# STM32MP25_CM33 register map
File version: 1.3
CPU: CM33 r0p1, little endian, MPU, FPU, vendor SysTick, 8 interrupt priority bits
Registers are 32-bit, read-write, reset 0x0 unless marked. A register's access mark holds for its fields unless they carry their own. Offsets are from the block's base; [hi:lo] are bit positions; {n}, {i} and the like mark numbered series; 'fields as' and 'values as' point back to an identical list.

## EXTI2 — EXTI2 address block description
Base 0x46230000
Same registers: EXTI2_S 0x56230000
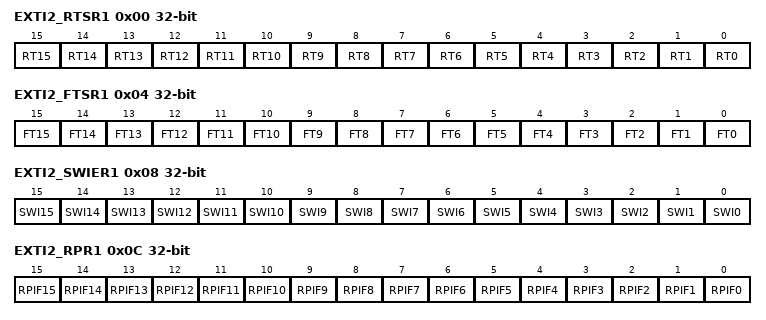
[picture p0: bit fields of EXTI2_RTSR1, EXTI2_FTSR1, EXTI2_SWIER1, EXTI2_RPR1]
0x00 EXTI2_RTSR1 — EXTI2 rising trigger selection register
  [15] RT15 — Rising trigger event configuration bit of configurable event input 15. When EXTI2_SECCFGR1.SEC15 is disabled, RT15 can be accessed with non-secure and secure access. When EXTI2_SECCFGR1.SEC15 is enabled, RT15 can only be accessed with secure access. Non-secure write to this bit x is discarded, non-secure read returns 0. When EXTI2_PRIVCFGR1.PRIV15 is disabled, RT15 can be accessed with unprivileged and privilege access. When EXTI2_PRIVCFGR1.PRIV15 is enabled, RT15 can only be accessed with privilege access. Unprivileged write to this bit x is discarded, unprivileged read returns 0. When CID filtering is disabled in EXTI2_E15CIDCFGR this RT15 can be accessed by any processor CID. When CID filtering is enabled in EXTI2_E15CIDCFGR this RT15 can only be accessed by the allowed processor CID. Illegal CID write to this RT15 is discarded and read returns 0. Note: The configurable event input is edge triggered. No glitch must be generated on this input. If a rising edge on the configurable event input occurs while writing to the register, the associated pending bit is not set. Rising and falling edge triggers can be set for the same configurable event input. In this case, both edges generate a trigger.
    0=Rising trigger disabled (for event and Interrupt) for input line; 1=Rising trigger enabled (for event and Interrupt) for input line
  [n] RT{n} (n=0..14) — Rising trigger event configuration bit of configurable event input {n}.
0x04 EXTI2_FTSR1 — EXTI2 falling trigger selection register
  [15] FT15 — Falling trigger event configuration bit of configurable event input 15. When EXTI2_SECCFGR1.SEC15 is disabled, FT15 can be accessed with non-secure and secure access. When EXTI2_SECCFGR1.SEC15 is enabled, FT15 can only be accessed with secure access. Non-secure write to this FT15 is discarded, non-secure read returns 0. When EXTI2_PRIVCFGR1.PRIV15 is disabled, FT15 can be accessed with unprivileged and privilege access. When EXTI2_PRIVCFGR1.PRIV15 is enabled, FT15 can only be accessed with privilege access. Unprivileged write to this FT15 is discarded, unprivileged read returns 0. When CID filtering is disabled in EXTI2_E15CIDCFGR this FT15 can be accessed by any processor CID. When CID filtering is enabled in EXTI2_E15CIDCFGR this FT15 can only be accessed by the allowed processor CID. Dis allowed CID write to this FT15 is discarded and read returns 0. Note: The configurable event input is edge triggered. No glitch must be generated on this input. If a falling edge on the configurable event input occurs while writing to the register, the associated pending bit is not set. Rising and falling edge triggers can be set for the same configurable event input. In this case, both edges generate a trigger.
    0=Falling trigger disabled (for event and Interrupt) for input line; 1=Falling trigger enabled (for event and Interrupt) for input line
  [n] FT{n} (n=0..14) — Falling trigger event configuration bit of configurable event input {n}.
0x08 EXTI2_SWIER1 — EXTI2 software interrupt event register
  [15] SWI15 — Software interrupt on event 15. When EXTI2_SECCFGR1.SEC15 is disabled, SWI15 can be accessed with non-secure and secure access. When EXTI2_SECCFGR1.SEC15 is enabled, SWI15 can only be accessed with secure access. Non-secure write to this SWI15 is discarded, non-secure read returns 0. When EXTI2_PRIVCFGR1.PRIV15 is disabled, SWI15 can be accessed with unprivileged and privilege access. When EXTI2_PRIVCFGR1.PRIV15 is enabled, SWI15 can only be accessed with privilege access. Unprivileged write to this SWI15 is discarded, unprivileged read returns 0. When CID filtering is disabled in EXTI2_E15CIDCFGR this SWI15 can be accessed by any processor CID. When CID filtering is enabled in EXTI2_E15CIDCFGR this SWI15 can only be accessed by the allowed processor CID. Dis allowed CID write to this SWI15 is discarded and read returns 0. A software interrupt is generated independent from the setting in EXTI2_RTSR and EXTI2_FTSR. It always returns 0 when read.
    0=Writing 0 has no effect; 1=Writing a 1 to this bit triggers a rising edge event on event 15. This bit is auto cleared by HW.
  [n] SWI{n} (n=0..14) — Software interrupt on event {n}.
0x0C EXTI2_RPR1 — EXTI2 rising edge pending register
  [15] RPIF15 — configurable event input 15 rising edge Pending bit. When EXTI2_SECCFGR1.SEC15 is disabled, RPIF15 can be accessed with non-secure and secure access. When EXTI2_SECCFGR1.SEC15 is enabled, RPIF15 can only be accessed with secure access. Non-secure write to this RPIF15 is discarded, non-secure read returns 0. When EXTI2_PRIVCFGR1.PRIV15 is disabled, RPIF15 can be accessed with unprivileged and privilege access. When EXTI2_PRIVCFGR1.PRIV15 is enabled, RPIF15 can only be accessed with privilege access. Unprivileged write to this RPIF15 is discarded, unprivileged read returns 0. When CID filtering is disabled in EXTI2_E15CIDCFGR this RPIF15 can be accessed by any processor CID. When CID filtering is enabled in EXTI2_E15CIDCFGR this RPIF15 can only be accessed by the allowed processor CID. Dis allowed CID write to this RPIF15 is discarded and read returns 0. This bit is set when the selected rising edge event or an EXTI2_SWIER Software trigger arrives on the configurable event line. This bit is cleared by writing a 1 into the bit.
    0=No rising edge trigger request occurred; 1=selected rising edge trigger request occurred
  [n] RPIF{n} (n=6..14) — configurable event input {n} rising edge Pending bit.
  [5] RPIF5 — configurable event input 5 rising edge Pending bit
  [n] RPIF{n} (n=0..4) — configurable event input {n} rising edge Pending bit.
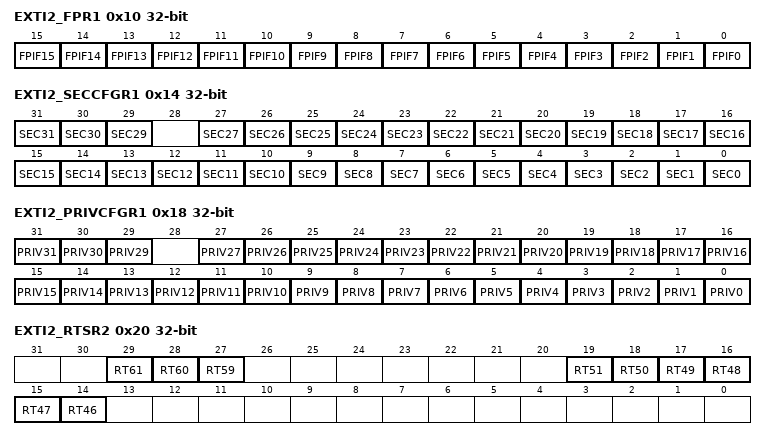
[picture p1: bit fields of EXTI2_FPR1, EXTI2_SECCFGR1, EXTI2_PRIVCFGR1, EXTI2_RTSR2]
0x10 EXTI2_FPR1 — EXTI2 falling edge pending register
  [15] FPIF15 — configurable event input 15 falling edge pending bit. When EXTI2_SECCFGR1.SEC15 is disabled, FPIF15 can be accessed with non-secure and secure access. When EXTI2_SECCFGR1.SEC15 is enabled, FPIF15 can only be accessed with secure access. Non-secure write to this FPIF15 is discarded, non-secure read returns 0. When EXTI2_PRIVCFGR1.PRIV15 is disabled, FPIF15 can be accessed with unprivileged and privilege access. When EXTI2_PRIVCFGR1.PRIV15 is enabled, FPIF15 can only be accessed with privilege access. Unprivileged write to this FPIF15 is discarded, unprivileged read returns 0. When CID filtering is disabled in EXTI2_E15CIDCFGR this FPIF15 can be accessed by any processor CID. When CID filtering is enabled in EXTI2_E15CIDCFGR this FPIF15 can only be accessed by the allowed processor CID. Dis allowed CID write to this FPIF15 is discarded and read returns 0. This bit is set when the falling edge event arrives on the configurable event line. This bit is cleared by writing a 1 into the bit.
    0=No falling edge trigger request occurred; 1=falling edge trigger request occurred
  [n] FPIF{n} (n=0..14) — configurable event input {n} falling edge pending bit.
0x14 EXTI2_SECCFGR1 — EXTI2 security configuration register
  [31] SEC31 — Security enable on event input 31. When CID filtering is disabled in EXTI2_E31CIDCFGR this SEC31 can be accessed by any processor CID. When CID filtering is enabled in EXTI2_E31CIDCFGR this SEC31 can only be accessed by the allowed processor CID. Dis allowed CID write to this SEC31 is discarded and read returns 0.
    0=Event security disabled (non-secure); 1=Event security enabled (secure)
  [30] SEC30 — Security enable on event input 30.
  [29] SEC29 — Security enable on event input 29.
  [n] SEC{n} (n=0..27) — Security enable on event input n. (where n = 27 to 0)
0x18 EXTI2_PRIVCFGR1 — EXTI2 Privilege configuration register
  [31] PRIV31 — Privilege enable on event input 31. When EXTI2_SECCFGR1.SEC31 is disabled, PRIV31 can be accessed with secure and non-secure access. When EXTI2_SECCFGR1.SEC31 is enabled, PRIV31 can only be written with secure access. Non-secure write to this PRIV31 is discarded. When CID filtering is disabled in EXTI2_E31CIDCFGR this PRIV31 can be accessed by any processor CID. When CID filtering is enabled in EXTI2_E31CIDCFGR this PRIV31 can only be accessed by the allowed processor CID. Dis allowed CID write to this PRIV31 is discarded and read returns 0.
    0=Event privilege disabled (Unprivileged); 1=Event privilege enabled (Privileged)
  [30] PRIV30 — Privilege enable on event input 30.
  [29] PRIV29 — Privilege enable on event input 29.
  [n] PRIV{n} (n=0..27) — Privilege enable on event input n. (where n = 27 to 0)
0x20 EXTI2_RTSR2 — EXTI2 rising trigger selection register
  [29] RT61 — Rising trigger event configuration bit of configurable event input 61. When EXTI2_SECCFGR2.SEC61 is disabled, RT61 can be accessed with non-secure and secure access. When EXTI2_SECCFGR2.SEC61 is enabled, RT61 can only be accessed with secure access. Non-secure write to this RT61 is discarded, non-secure read returns 0. When EXTI2_PRIVCFGR2.PRIV61 is disabled, RT61 can be accessed with unprivileged and privilege access. When EXTI2_PRIVCFGR2.PRIV61 is enabled, RT61 can only be accessed with privilege access. Unprivileged write to this RT61 is discarded, unprivileged read returns 0. When CID filtering is disabled in EXTI2_E61CIDCFGR this RT61 can be accessed by any processor CID. When CID filtering is enabled in EXTI2_E61CIDCFGR this RT61 can only be accessed by the allowed processor CID. Dis allowed CID write to this RT61 is discarded and read returns 0. Note: The configurable event input is edge triggered. No glitch must be generated on this input. If a rising edge on the configurable event input occurs while writing to the register, the associated pending bit is not set. Rising and falling edge triggers can be set for the same configurable event input. In this case, both edges generate a trigger.
    0=Rising trigger disabled (for event and interrupt) for input line; 1=Rising trigger enabled (for event and interrupt) for input line
  [28] RT60 — Rising trigger event configuration bit of configurable event input 60.
  [27] RT59 — Rising trigger event configuration bit of configurable event input 59.
  [n-32] RT{n} (n=46..51) — Rising trigger event configuration bit of configurable event input {n}.
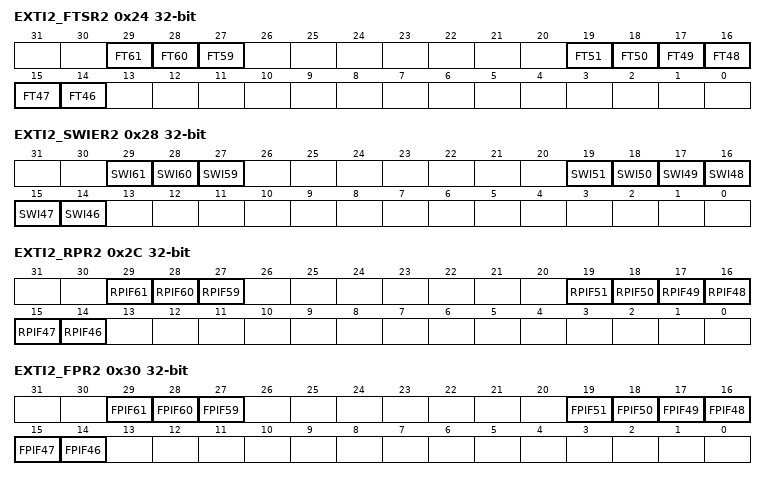
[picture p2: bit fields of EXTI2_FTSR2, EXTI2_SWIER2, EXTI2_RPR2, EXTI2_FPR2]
0x24 EXTI2_FTSR2 — EXTI2 falling trigger selection register
  [29] FT61 — Falling trigger event configuration bit of configurable event input 61. When EXTI2_SECCFGR2.SEC61 is disabled, FT61 can be accessed with non-secure and secure access. When EXTI2_SECCFGR2.SEC61 is enabled, FT61 can only be accessed with secure access. Non-secure write to this FT61 is discarded, non-secure read returns 0. When EXTI2_PRIVCFGR2.PRIV61 is disabled, FT61 can be accessed with unprivileged and privilege access. When EXTI2_PRIVCFGR2.PRIV61 is enabled, FT61 can only be accessed with privilege access. Unprivileged write to this FT61 is discarded, unprivileged read returns 0. When CID filtering is disabled in EXTI2_E61CIDCFGR this FT61 can be accessed by any processor CID. When CID filtering is enabled in EXTI2_E61CIDCFGR this FT61 can only be accessed by the allowed processor CID. Dis allowed CID write to this FT61 is discarded and read returns 0. Note: The configurable event input is edge triggered. No glitch must be generated on this input. If a falling edge on the configurable event input occurs while writing to the register, the associated pending bit is not set. Rising and falling edge triggers can be set for the same configurable event input. In this case, both edges generate a trigger.
    0=Falling trigger disabled (for event and interrupt) for input line; 1=Falling trigger enabled (for event and interrupt) for input line
  [28] FT60 — Falling trigger event configuration bit of configurable event input 60.
  [27] FT59 — Falling trigger event configuration bit of configurable event input 59.
  [n-32] FT{n} (n=46..51) — Falling trigger event configuration bit of configurable event input {n}.
0x28 EXTI2_SWIER2 — EXTI2 software interrupt event register
  [29] SWI61 — Software interrupt on event 61. When EXTI2_SECCFGR2.SEC61 is disabled, SWI61 can be accessed with non-secure and secure access. When EXTI2_SECCFGR2.SEC61 is enabled, SWI61 can only be accessed with secure access. Non-secure write to this SWI61 is discarded, non-secure read returns 0. When EXTI2_PRIVCFGR2.PRIV61 is disabled, SWI61 can be accessed with unprivileged and privilege access. When EXTI2_PRIVCFGR2.PRIV61 is enabled, SWI61 can only be accessed with privilege access. Unprivileged write to this SWI61 is discarded, unprivileged read returns 0. When CID filtering is disabled in EXTI2_E61CIDCFGR this SWI61 can be accessed by any processor CID. When CID filtering is enabled in EXTI2_E61CIDCFGR this SWI61 can only be accessed by the allowed processor CID. Dis allowed CID write to this SWI61 is discarded and read returns 0. A software interrupt is generated independent from the setting in EXTI2_RTSR and EXTI2_FTSR. It always returns 0 when read.
    0=Writing 0 has no effect; 1=Writing a 1 to this bit triggers a rising edge event on event 61. This bit is auto cleared by HW.
  [28] SWI60 — Software interrupt on event 60.
  [27] SWI59 — Software interrupt on event 59.
  [n-32] SWI{n} (n=46..51) — Software interrupt on event {n}.
0x2C EXTI2_RPR2 — EXTI2 rising edge pending register
  [29] RPIF61 — configurable event input 61 rising edge Pending bit. When EXTI2_SECCFGR2.SEC61 is disabled, RPIF61 can be accessed with non-secure and secure access. When EXTI2_SECCFGR2.SEC61 is enabled, RPIF61 can only be accessed with secure access. Non-secure write to this RPIF61 is discarded, non-secure read returns 0. When EXTI2_PRIVCFGR2.PRIV61 is disabled, RPIF ca61 be accessed with unprivileged and privilege access. When EXTI2_PRIVCFGR2.PRIV61 is enabled, RPIF61 can only be accessed with privilege access. Unprivileged write to this RPIF61 is discarded, unprivileged read returns 0. When CID filtering is disabled in EXTI2_E61CIDCFGR this RPIF61 can be accessed by any processor CID. When CID filtering is enabled in EXTI2_E61CIDCFGR this RPIF61 can only be accessed by the allowed processor CID. Dis allowed CID write to this RPIF61 is discarded and read returns 0. This bit is set when the selected rising edge event or an EXTI2_SWIER Software trigger arrives on the configurable event line. This bit is cleared by writing a 1 into the bit.
    values as EXTI2_RPR1.RPIF15
  [28] RPIF60 — configurable event input 60 rising edge Pending bit.
  [27] RPIF59 — configurable event input 59 rising edge Pending bit.
  [n-32] RPIF{n} (n=46..51) — configurable event input {n} rising edge Pending bit.
0x30 EXTI2_FPR2 — EXTI2 falling edge pending register
  [29] FPIF61 — configurable event input 61 pending bit. When EXTI2_SECCFGR2.SEC61 is disabled, FPIF61 can be accessed with non-secure and secure access. When EXTI2_SECCFGR2.SEC61 is enabled, FPIF61 can only be accessed with secure access. Non-secure write to this FPIF61 is discarded, non-secure read returns 0. When EXTI2_PRIVCFGR2.PRIV61 is disabled, FPIF61 can be accessed with unprivileged and privilege access. When EXTI2_PRIVCFGR2.PRIV61 is enabled, FPIF61 can only be accessed with privilege access. Unprivileged write to this FPIF61 is discarded, unprivileged read returns 0. When CID filtering is disabled in EXTI2_E61CIDCFGR this FPIF61 can be accessed by any processor CID. When CID filtering is enabled in EXTI2_E61CIDCFGR this FPIF61 can only be accessed by the allowed processor CID. Dis allowed CID write to this FPIF61 is discarded and read returns 0. This bit is set when the falling edge event arrives on the configurable event line. This bit is cleared by writing a 1 into the bit.
    values as EXTI2_FPR1.FPIF15
  [28] FPIF60 — configurable event input 60 pending bit.
  [27] FPIF59 — configurable event input 59 pending bit.
  [n-32] FPIF{n} (n=46..51) — configurable event input {n} pending bit.
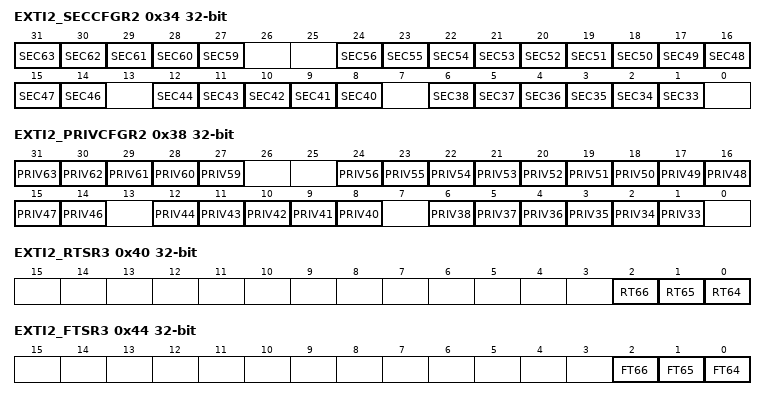
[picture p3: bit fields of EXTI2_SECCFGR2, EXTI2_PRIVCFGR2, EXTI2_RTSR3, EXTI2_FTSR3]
0x34 EXTI2_SECCFGR2 — EXTI2 security enable register
  [31] SEC63 — Security enable on event input 63. When CID filtering is disabled in EXTI2_E63CIDCFGR this SEC63 can be accessed by any processor CID. When CID filtering is enabled in EXTI2_E63CIDCFGR this SEC63 can only be accessed by the allowed processor CID. Dis allowed CID write to this SEC63 is discarded and read returns 0.
    values as EXTI2_SECCFGR1.SEC31
  [n-32] SEC{n} (n=59..62) — Security enable on event input {n}.
  [n-32] SEC{n} (n=46..56) — Security enable on event input {n}.
  [n-32] SEC{n} (n=40..44) — Security enable on event input {n}.
  [n-32] SEC{n} (n=33..38) — Security enable on event input {n}.
0x38 EXTI2_PRIVCFGR2 — EXTI2 Privilege enable register
  [31] PRIV63 — Privilege enable on event input 63. When EXTI2_SECCFGR2.SEC63 is disabled, PRIV63 can be accessed with secure and non-secure access. When EXTI2_SECCFGR2.SEC63 is enabled, PRIV63 can only be accessed with secure access. Non-secure write to this PRIV63 is discarded. When CID filtering is disabled in EXTI2_E63CIDCFGR this PRIV63 can be accessed by any processor CID. When CID filtering is enabled in EXTI2_E63CIDCFGR this PRIV63 can only be accessed by the allowed processor CID. Dis allowed CID write to this PRIV63 is discarded and read returns 0.
    values as EXTI2_PRIVCFGR1.PRIV31
  [n-32] PRIV{n} (n=59..62) — Privilege enable on event input {n}.
  [n-32] PRIV{n} (n=46..56) — Privilege enable on event input {n}.
  [n-32] PRIV{n} (n=40..44) — Privilege enable on event input {n}.
  [n-32] PRIV{n} (n=33..38) — Privilege enable on event input {n}.
0x40 EXTI2_RTSR3 — EXTI2 rising trigger selection register
  [2] RT66 — Rising trigger event configuration bit of configurable event input 66. When EXTI2_SECCFGR3.SEC66 is disabled, RT66 can be accessed with non-secure and secure access. When EXTI2_SECCFGR3.SEC66 is enabled, RT66 can only be accessed with secure access. Non-secure write to this RT66 is discarded, non-secure read returns 0. When EXTI2_PRIVCFGR3.PRIV66 is disabled, RT66 can be accessed with unprivileged and privilege access. When EXTI2_PRIVCFGR3.PRIV66 is enabled, RT66 can only be accessed with privilege access. Unprivileged write to this RT66 is discarded, unprivileged read returns 0. When CID filtering is disabled in EXTI2_E66CIDCFGR this RT66 can be accessed by any processor CID. When CID filtering is enabled in EXTI2_E66CIDCFGR this RT66 can only be accessed by the allowed processor CID. Illegal CID write to this RT66 is discarded and read returns 0. Note: The configurable event input is edge triggered. No glitch must be generated on this input. If a rising edge on the configurable event input occurs while writing to the register, the associated pending bit is not set. Rising and falling edge triggers can be set for the same configurable event input. In this case, both edges generate a trigger.
    values as EXTI2_RTSR2.RT61
  [1] RT65 — Rising trigger event configuration bit of configurable event input 65.
  [0] RT64 — Rising trigger event configuration bit of configurable event input 64.
0x44 EXTI2_FTSR3 — EXTI2 falling trigger selection register
  [2] FT66 — Falling trigger event configuration bit of configurable event input 66. When EXTI2_SECCFGR3.SEC66 is disabled, FT66 can be accessed with non-secure and secure access. When EXTI2_SECCFGR3.SEC66 is enabled, FT66 can only be accessed with secure access. Non-secure write to this FT66 is discarded, non-secure read returns 0. When EXTI2_PRIVCFGR3.PRIV66 is disabled, FT66 can be accessed with unprivileged and privilege access. When EXTI2_PRIVCFGR3.PRIV66 is enabled, FT66 can only be accessed with privilege access. Unprivileged write to this FT66 is discarded, unprivileged read returns 0. When CID filtering is disabled in EXTI2_E66CIDCFGR this FT66 can be accessed by any processor CID. When CID filtering is enabled in EXTI2_E66CIDCFGR this FT66 can only be accessed by the allowed processor CID. Dis allowed CID write to this FT66 is discarded and read returns 0. Note: The configurable event input is edge triggered. No glitch must be generated on this input. If a falling edge on the configurable event input occurs while writing to the register, the associated pending bit is not set. Rising and falling edge triggers can be set for the same configurable event input. In this case, both edges generate a trigger.
    values as EXTI2_FTSR2.FT61
  [1] FT65 — Falling trigger event configuration bit of configurable event input 65.
  [0] FT64 — Falling trigger event configuration bit of configurable event input 64.
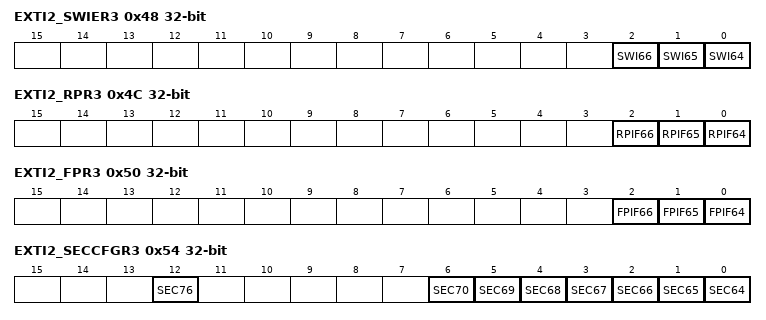
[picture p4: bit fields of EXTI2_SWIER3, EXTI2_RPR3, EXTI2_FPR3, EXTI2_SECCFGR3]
0x48 EXTI2_SWIER3 — EXTI2 software interrupt event register
  [2] SWI66 — Software interrupt on event 66. When EXTI2_SECCFGR3.SEC66 is disabled, SWI66 can be accessed with non-secure and secure access. When EXTI2_SECCFGR3.SEC66 is enabled, SWI66 can only be accessed with secure access. Non-secure write to this SWI66 is discarded, non-secure read returns 0. When EXTI2_PRIVCFGR3.PRIV66 is disabled, SWI66 can be accessed with unprivileged and privilege access. When EXTI2_PRIVCFGR3.PRIV66 is enabled, SWI66 can only be accessed with privilege access. Unprivileged write to this SWI66 is discarded, unprivileged read returns 0. When CID filtering is disabled in EXTI2_E66CIDCFGR this SWI66 can be accessed by any processor CID. When CID filtering is enabled in EXTI2_E66CIDCFGR this SWI66 can only be accessed by the allowed processor CID. Dis allowed CID write to this SWI66 is discarded and read returns 0. A software interrupt is generated independent from the setting in EXTI2_RTSR and EXTI2_FTSR. It always returns 0 when read.
    0=Writing 1 has no effect; 1=Writing a 1 to this bit triggers a rising edge event on event 66. This bit is auto cleared by HW.
  [1] SWI65 — Software interrupt on event 65.
  [0] SWI64 — Software interrupt on event 64.
0x4C EXTI2_RPR3 — EXTI2 rising edge pending register
  [2] RPIF66 — configurable event input 66 rising edge pending bit. When EXTI2_SECCFGR3.SEC66 is disabled, RPIF66 can be accessed with non-secure and secure access. When EXTI2_SECCFGR3.SEC66 is enabled, RPIF66 can only be accessed with secure access. Non-secure write to this RPIF66 is discarded, non-secure read returns 0. When EXTI2_PRIVCFGR3.PRIV66 is disabled, RPIF66 can be accessed with unprivileged and privilege access. When EXTI2_PRIVCFGR3.PRIV66 is enabled, RPIF66 can only be accessed with privilege access. Unprivileged write to this RPIF66 is discarded, unprivileged read returns 0. When CID filtering is disabled in EXTI2_E66CIDCFGR this RPIF66 can be accessed by any processor CID. When CID filtering is enabled in EXTI2_E66CIDCFGR this RPIF66 can only be accessed by the allowed processor CID. Dis allowed CID write to this RPIF66 is discarded and read returns 0. This bit is set when the selected rising edge event or an EXTI2_SWIER Software trigger arrives on the configurable event line. This bit is cleared by writing a 1 into the bit.
    values as EXTI2_RPR1.RPIF15
  [1] RPIF65 — configurable event input 65 rising edge pending bit.
  [0] RPIF64 — configurable event input 64 rising edge pending bit.
0x50 EXTI2_FPR3 — EXTI2 falling edge pending register
  [2] FPIF66 — configurable event input 66 falling edge pending bit. When EXTI2_SECCFGR3.SEC66 is disabled, FPIF66 can be accessed with non-secure and secure access. When EXTI2_SECCFGR3.SEC66 is enabled, FPIF66 can only be accessed with secure access. Non-secure write to this FPIF66 is discarded, non-secure read returns 0. When EXTI2_PRIVCFGR3.PRIV66 is disabled, FPIF66 can be accessed with unprivileged and privilege access. When EXTI2_PRIVCFGR3.PRIV66 is enabled, FPIF66 can only be accessed with privilege access. Unprivileged write to this FPIF66 is discarded, unprivileged read returns 0. When CID filtering is disabled in EXTI2_E66CIDCFGR this FPIF66 can be accessed by any processor CID. When CID filtering is enabled in EXTI2_E66CIDCFGR this FPIF66 can only be accessed by the allowed processor CID. Dis allowed CID write to this FPIF66 is discarded and read returns 0. This bit is set when the falling edge event arrives on the configurable event line. This bit is cleared by writing a 1 into the bit.
    values as EXTI2_FPR1.FPIF15
  [1] FPIF65 — configurable event input 65 falling edge pending bit.
  [0] FPIF64 — configurable event input 64 falling edge pending bit.
0x54 EXTI2_SECCFGR3 — EXTI2 security enable register
  [12] SEC76 — Security enable on event input 76. When CID filtering is disabled in EXTI2_E76CIDCFGR this SEC76 can be accessed by any processor CID. When CID filtering is enabled in EXTI2_E76CIDCFGR this SEC76 can only be accessed by the allowed processor CID. Dis allowed CID write to this SEC76 is discarded and read returns 0.
    values as EXTI2_SECCFGR1.SEC31
  [n-64] SEC{n} (n=64..70) — Security enable on event input {n}.
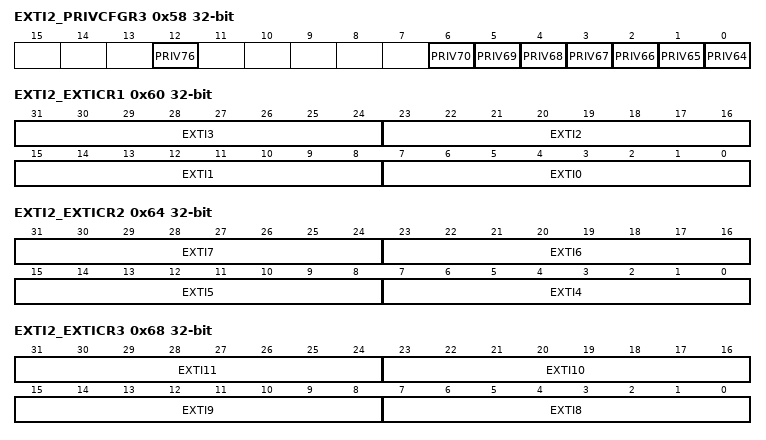
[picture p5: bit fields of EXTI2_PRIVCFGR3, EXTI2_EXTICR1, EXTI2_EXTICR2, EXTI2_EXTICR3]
0x58 EXTI2_PRIVCFGR3 — EXTI2 Privilege enable register
  [12] PRIV76 — Privilege enable on event input 76. When EXTI2_SECCFGR3.SEC76 is disabled, PRIV76 can be accessed with secure and non-secure access. When EXTI2_SECCFGR3.SEC76 is enabled, PRIV76 can only be written with secure access. Non-secure write to this PRIV76 is discarded. When CID filtering is disabled in EXTI2_E76CIDCFGR this PRIV76 can be accessed by any processor CID. When CID filtering is enabled in EXTI2_E76CIDCFGR this PRIV76 can only be accessed by the allowed processor CID. Dis allowed CID write to this PRIV76 is discarded and read returns 0.
    values as EXTI2_PRIVCFGR1.PRIV31
  [n-64] PRIV{n} (n=64..70) — Privilege enable on event input {n}.
0x60 EXTI2_EXTICR1
  [31:24] EXTI3 — EXTI3 GPIO port selection. These bits are written by software to select the source input for EXTI3 external interrupt. When EXTI2_SECCFGR1.SEC3 is disabled, EXTI3 can be accessed with non-secure and secure access. When EXTI2_SECCFGR1.SEC3 is enabled, EXTI3 can only be accessed with secure access. Non-secure write is discarded, non-secure read returns 0. When EXTI2_PRIVCFGR1.PRIV3 is disabled, EXTI3 can be accessed with privilege and unprivileged access. When EXTI2_PRIVCFGR1.PRIV3 is enabled, EXTI3 can only be accessed with privilege access. Unprivileged write to this bit is discarded and read returns 0. When CID filtering in EXTI2_E3CIDCFGR is disabled, EXTI3 can be accessed by any processor CID. When CID filtering in EXTI2_E3CIDCFGR is enabled, EXTI3 can only be accessed by the allowed processor CID. Dis allowed CID write to EXTI3 is discarded and read returns 0. Others: reserved
    0=PA3 pin; 1=PB3 pin; 2=PC3 pin; 3=PD3 pin; 4=PE3 pin; 5=PF3 pin; 6=PG3 pin; 7=PH3 pin; 8=PI3 pin; 9=PJ3 pin; 10=PK3 pin; 11=PZ3 pin
  [23:16] EXTI2 — EXTI2 GPIO port selection. These bits are written by software to select the source input for EXTI2 external interrupt. When EXTI2_SECCFGR1.SEC2 is disabled, EXTI2 can be accessed with non-secure and secure access. When EXTI2_SECCFGR1.SEC2 is enabled, EXTI2 can only be accessed with secure access. Non-secure write is discarded, non-secure read returns 0. When EXTI2_PRIVCFGR1.PRIV2 is disabled, EXTI2 can be accessed with privilege and unprivileged access. When EXTI2_PRIVCFGR1.PRIV2 is enabled, EXTI2 can only be accessed with privilege access. Unprivileged write to this bit is discarded and read returns 0. When CID filtering in EXTI2_E2CIDCFGR is disabled, EXTI2 can be accessed by any processor CID. When CID filtering in EXTI2_E2CIDCFGR is enabled, EXTI2 can only be accessed by the allowed processor CID. Dis allowed CID write to EXTI2 is discarded and read returns 0. Others: reserved
    0=PA2 pin; 1=PB2 pin; 2=PC2 pin; 3=PD2 pin; 4=PE2 pin; 5=PF2 pin; 6=PG2 pin; 7=PH2 pin; 8=PI2 pin; 9=PJ2 pin; 10=PK2 pin; 11=PZ2 pin
  [15:8] EXTI1 — EXTI1 GPIO port selection. These bits are written by software to select the source input for EXTI1 external interrupt. When EXTI2_SECCFGR1.SEC1 is disabled, EXTI1 can be accessed with non-secure and secure access. When EXTI2_SECCFGR1.SEC1 is enabled, EXTI1 can only be accessed with secure access. Non-secure write is discarded, non-secure read returns 0. When EXTI2_PRIVCFGR1.PRIV1 is disabled, EXTI1 can be accessed with privilege and unprivileged access. When EXTI2_PRIVCFGR1.PRIV1 is enabled, EXTI1 can only be accessed with privilege access. Unprivileged write to this bit is discarded and read returns 0. When CID filtering in EXTI2_E1CIDCFGR is disabled, EXTI1 can be accessed by any processor CID. When CID filtering in EXTI2_E1CIDCFGR is enabled, EXTI1 can only be accessed by the allowed processor CID. Dis allowed CID write to EXTI1 is discarded and read returns 0. Others: reserved
    0=PA1 pin; 1=PB1 pin; 2=PC1 pin; 3=PD1 pin; 4=PE1 pin; 5=PF1 pin; 6=PG1 pin; 7=PH1 pin; 8=PI1 pin; 9=PJ1 pin; 10=PK1 pin; 11=PZ1 pin
  [7:0] EXTI0 — EXTI0 GPIO port selection. These bits are written by software to select the source input for EXTIm external interrupt. When EXTI2_SECCFGR1.SEC0 is disabled, EXTI0 can be accessed with non-secure and secure access. When EXTI2_SECCFGR1.SEC0 is enabled, EXTI0 can only be accessed with secure access. Non-secure write is discarded, non-secure read returns 0. When EXTI2_PRIVCFGR1.PRIV0 is disabled, EXTI0 can be accessed with privilege and unprivileged access. When EXTI2_PRIVCFGR1.PRIV0 is enabled, EXTI0 can only be accessed with privilege access. Unprivileged write to this bit is discarded and read returns 0. When CID filtering in EXTI2_E0CIDCFGR is disabled, EXTI0 can be accessed by any processor CID. When CID filtering in EXTI2_E0CIDCFGR is enabled, EXTI0 can only be accessed by the allowed processor CID. Dis allowed CID write to EXTI0 is discarded and read returns 0. Others: reserved
    0=PA0 pin; 1=PB0 pin; 2=PC0 pin; 3=PD0 pin; 4=PE0 pin; 5=PF0 pin; 6=PG0 pin; 7=PH0 pin; 8=PI0 pin; 9=PJ0 pin; 10=PK0 pin; 11=PZ0 pin
0x64 EXTI2_EXTICR2
  [8n-25:8n-32] EXTI{n} (n=4..7) — EXTI{n} GPIO port selection. These bits are written by software to select the source input for EXTI{n} external interrupt. When EXTI2_SECCFGR1.SEC{n} is disabled, EXTI{n} can be accessed with non-secure and secure access. When EXTI2_SECCFGR1.SEC{n} is enabled, EXTI{n} can only be accessed with secure access. Non-secure write is discarded, non-secure read returns 0. When EXTI2_PRIVCFGR1.PRIV{n} is disabled, EXTI{n} can be accessed with privilege and unprivileged access. When EXTI2_PRIVCFGR1.PRIV{n} is enabled, EXTI{n} can only be accessed with privilege access. Unprivileged write to this bit is discarded and read returns 0. When CID filtering in EXTI2_E{n}CIDCFGR is disabled, EXTI{n} can be accessed by any processor CID. When CID filtering in EXTI2_E{n}CIDCFGR is enabled, EXTI{n} can only be accessed by the allowed processor CID. Dis allowed CID write to EXTI{n} is discarded and read returns 0. Others: reserved
    0=PA{n} pin; 1=PB{n} pin; 2=PC{n} pin; 3=PD{n} pin; 4=PE{n} pin; 5=PF{n} pin; 6=PG{n} pin; 7=PH{n} pin; 8=PI{n} pin; 9=PJ{n} pin; 10=PK{n} pin; 11=PZ{n} pin
0x68 EXTI2_EXTICR3
  [31:24] EXTI11 — EXTI11 GPIO port selection. These bits are written by software to select the source input for EXTI11 external interrupt. When EXTI2_SECCFGR1.SEC11 is disabled, EXTI11 can be accessed with non-secure and secure access. When EXTI2_SECCFGR1.SEC11 is enabled, EXTI11 can only be accessed with secure access. Non-secure write is discarded, non-secure read returns 0. When EXTI2_PRIVCFGR1.PRIV11 is disabled, EXTI11 can be accessed with privilege and unprivileged access. When EXTI2_PRIVCFGR1.PRIV11 is enabled, EXTI11 can only be accessed with privilege access. Unprivileged write to this bit is discarded and read returns 0. When CID filtering in EXTI2_E11CIDCFGR is disabled, EXTI11 can be accessed by any processor CID. When CID filtering in EXTI2_E11CIDCFGR is enabled, EXTI11 can only be accessed by the allowed processor CID. Dis allowed CID write to EXTI11 is discarded and read returns 0. Others: reserved
    0=PA11 pin; 1=PB11 pin; 2=PC11 pin; 3=PD11 pin; 4=PE11 pin; 5=PF11 pin; 6=PG11 pin; 7=PH11 pin; 8=PI11 pin; 9=PJ11 pin
  [23:16] EXTI10 — EXTI10 GPIO port selection. These bits are written by software to select the source input for EXTI10 external interrupt. When EXTI2_SECCFGR1.SEC10 is disabled, EXTI10 can be accessed with non-secure and secure access. When EXTI2_SECCFGR1.SEC10 is enabled, EXTI10 can only be accessed with secure access. Non-secure write is discarded, non-secure read returns 0. When EXTI2_PRIVCFGR1.PRIV10 is disabled, EXTI10 can be accessed with privilege and unprivileged access. When EXTI2_PRIVCFGR1.PRIV10 is enabled, EXTI10 can only be accessed with privilege access. Unprivileged write to this bit is discarded and read returns 0. When CID filtering in EXTI2_E10CIDCFGR is disabled, EXTI10 can be accessed by any processor CID. When CID filtering in EXTI2_E10CIDCFGR is enabled, EXTI10 can only be accessed by the allowed processor CID. Dis allowed CID write to EXTI10 is discarded and read returns 0. Others: reserved
    0=PA10 pin; 1=PB10 pin; 2=PC10 pin; 3=PD10 pin; 4=PE10 pin; 5=PF10 pin; 6=PG10 pin; 7=PH10 pin; 8=PI10 pin; 9=PJ10 pin
  [15:8] EXTI9 — EXTI9 GPIO port selection. These bits are written by software to select the source input for EXTI9 external interrupt. When EXTI2_SECCFGR1.SEC9 is disabled, EXTI9 can be accessed with non-secure and secure access. When EXTI2_SECCFGR1.SEC9 is enabled, EXTI9 can only be accessed with secure access. Non-secure write is discarded, non-secure read returns 0. When EXTI2_PRIVCFGR1.PRIV9 is disabled, EXTI9 can be accessed with privilege and unprivileged access. When EXTI2_PRIVCFGR1.PRIV9 is enabled, EXTI9 can only be accessed with privilege access. Unprivileged write to this bit is discarded and read returns 0. When CID filtering in EXTI2_E9CIDCFGR is disabled, EXTI9 can be accessed by any processor CID. When CID filtering in EXTI2_E9CIDCFGR is enabled, EXTI9 can only be accessed by the allowed processor CID. Dis allowed CID write to EXTI9 is discarded and read returns 0. Others: reserved
    0=PA9 pin; 1=PB9 pin; 2=PC9 pin; 3=PD9 pin; 4=PE9 pin; 5=PF9 pin; 6=PG9 pin; 7=PH9 pin; 8=PI9 pin; 9=PJ9 pin; 11=PZ9 pin
  [7:0] EXTI8 — EXTI8 GPIO port selection. These bits are written by software to select the source input for EXTI8 external interrupt. When EXTI2_SECCFGR1.SEC8 is disabled, EXTI8 can be accessed with non-secure and secure access. When EXTI2_SECCFGR1.SEC8 is enabled, EXTI8 can only be accessed with secure access. Non-secure write is discarded, non-secure read returns 0. When EXTI2_PRIVCFGR1.PRIV8 is disabled, EXTI8 can be accessed with privilege and unprivileged access. When EXTI2_PRIVCFGR1.PRIV8 is enabled, EXTI8 can only be accessed with privilege access. Unprivileged write to this bit is discarded and read returns 0. When CID filtering in EXTI2_E8CIDCFGR is disabled, EXTI8 can be accessed by any processor CID. When CID filtering in EXTI2_E8CIDCFGR is enabled, EXTI8 can only be accessed by the allowed processor CID. Dis allowed CID write to EXTI8 is discarded and read returns 0. Others: reserved
    0=PA8 pin; 1=PB8 pin; 2=PC8 pin; 3=PD8 pin; 4=PE8 pin; 5=PF8 pin; 6=PG8 pin; 7=PH8 pin; 8=PI8 pin; 9=PJ8 pin; 11=PZ8 pin
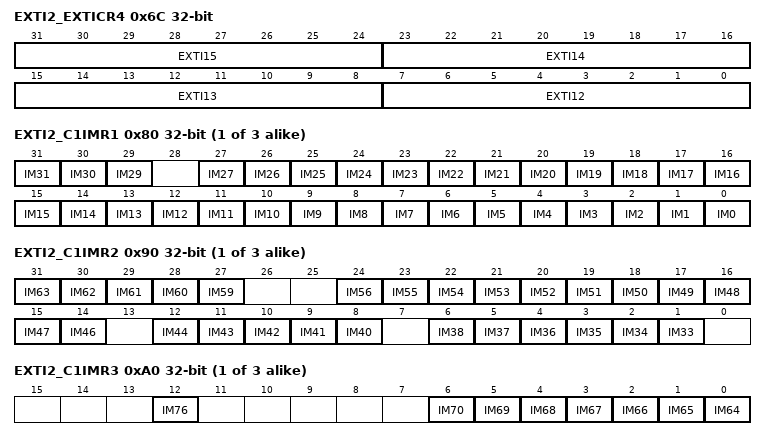
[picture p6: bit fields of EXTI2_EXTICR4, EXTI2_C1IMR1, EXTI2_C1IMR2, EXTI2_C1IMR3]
0x6C EXTI2_EXTICR4
  [31:24] EXTI15 — EXTI15 GPIO port selection. These bits are written by software to select the source input for EXTI15 external interrupt. When EXTI2_SECCFGR1.SEC15 is disabled, EXTI15 can be accessed with non-secure and secure access. When EXTI2_SECCFGR1.SEC15 is enabled, EXTI15 can only be accessed with secure access. Non-secure write is discarded, non-secure read returns 0. When EXTI2_PRIVCFGR1.PRIV15 is disabled, EXTI15 can be accessed with privilege and unprivileged access. When EXTI2_PRIVCFGR1.PRIV15 is enabled, EXTI15 can only be accessed with privilege access. Unprivileged write to this bit is discarded and read returns 0. When CID filtering in EXTI2_E15CIDCFGR is disabled, EXTI15 can be accessed by any processor CID. When CID filtering in EXTI2_E15CIDCFGR is enabled, EXTI15 can only be accessed by the allowed processor CID. Dis allowed CID write to EXTI15 is discarded and read returns 0. Others: reserved
    0=PA15 pin; 1=PB15 pin; 2=PC15 pin; 3=PD15 pin; 4=PE15 pin; 5=PF15 pin; 6=PG15 pin; 8=PI15 pin; 9=PJ15 pin
  [23:16] EXTI14 — EXTI14 GPIO port selection. These bits are written by software to select the source input for EXTI14 external interrupt. When EXTI2_SECCFGR1.SEC14 is disabled, EXTI14 can be accessed with non-secure and secure access. When EXTI2_SECCFGR1.SEC14 is enabled, EXTI14 can only be accessed with secure access. Non-secure write is discarded, non-secure read returns 0. When EXTI2_PRIVCFGR1.PRIV14 is disabled, EXTI14 can be accessed with privilege and unprivileged access. When EXTI2_PRIVCFGR1.PRIV14 is enabled, EXTI14 can only be accessed with privilege access. Unprivileged write to this bit is discarded and read returns 0. When CID filtering in EXTI2_E14CIDCFGR is disabled, EXTI14 can be accessed by any processor CID. When CID filtering in EXTI2_E14CIDCFGR is enabled, EXTI14 can only be accessed by the allowed processor CID. Dis allowed CID write to EXTI14 is discarded and read returns 0. Others: reserved
    0=PA14 pin; 1=PB14 pin; 2=PC14 pin; 3=PD14 pin; 4=PE14 pin; 5=PF14 pin; 6=PG14 pin; 8=PI14 pin; 9=PJ14 pin
  [15:8] EXTI13 — EXTI13 GPIO port selection. These bits are written by software to select the source input for EXTI13 external interrupt. When EXTI2_SECCFGR1.SEC13 is disabled, EXTI13 can be accessed with non-secure and secure access. When EXTI2_SECCFGR1.SEC13 is enabled, EXTI13 can only be accessed with secure access. Non-secure write is discarded, non-secure read returns 0. When EXTI2_PRIVCFGR1.PRIV13 is disabled, EXTI13 can be accessed with privilege and unprivileged access. When EXTI2_PRIVCFGR1.PRIV13 is enabled, EXTI13 can only be accessed with privilege access. Unprivileged write to this bit is discarded and read returns 0. When CID filtering in EXTI2_E13CIDCFGR is disabled, EXTI13 can be accessed by any processor CID. When CID filtering in EXTI2_E13CIDCFGR is enabled, EXTI13 can only be accessed by the allowed processor CID. Dis allowed CID write to EXTI13 is discarded and read returns 0. Others: reserved
    0=PA13 pin; 1=PB13 pin; 2=PC13 pin; 3=PD13 pin; 4=PE13 pin; 5=PF13 pin; 6=PG13 pin; 7=PH13 pin; 8=PI13 pin; 9=PJ13 pin
  [7:0] EXTI12 — EXTIp GPIO port selection. These bits are written by software to select the source input for EXTI12 external interrupt. When EXTI2_SECCFGR1.SEC12 is disabled, EXTI12 can be accessed with non-secure and secure access. When EXTI2_SECCFGR1.SEC12 is enabled, EXTI12 can only be accessed with secure access. Non-secure write is discarded, non-secure read returns 0. When EXTI2_PRIVCFGR1.PRIV12 is disabled, EXTI12 can be accessed with privilege and unprivileged access. When EXTI2_PRIVCFGR1.PRIV12 is enabled, EXTI12 can only be accessed with privilege access. Unprivileged write to this bit is discarded and read returns 0. When CID filtering in EXTI2_E12CIDCFGR is disabled, EXTI12 can be accessed by any processor CID. When CID filtering in EXTI2_E12CIDCFGR is enabled, EXTI12 can only be accessed by the allowed processor CID. Dis allowed CID write to EXTI12 is discarded and read returns 0. Others: reserved
    0=PA12 pin; 1=PB12 pin; 2=PC12 pin; 3=PD12 pin; 4=PE12 pin; 5=PF12 pin; 6=PG12 pin; 7=PH12 pin; 8=PI12 pin; 9=PJ12 pin
0x70 EXTI2_LOCKR — EXTI2 lock register
  [0] GLOCK — Global security, privilege and CID configuration registers EXTI2_SECCFGRx, EXTI2_PRIVCFGRx, EXTI2_EnCIDCFGR and EXTI2_CmCIDCFGR lock. This register bit is write once after reset.
    0=Security and privilege configuration open, can be modified; 1=Security and privilege configuration locked, can no longer be modified
{0x40+0x40*i} EXTI2_C{i}IMR1 (i=1..3) — EXTI2 CPU{i} wakeup with interrupt mask register
  [31] IM31 — CPUm wakeup with interrupt mask on event input 31. When EXTI2_SECCFGR1.SEC31 is disabled, IM31 can be accessed with non-secure and secure access. When EXTI2_SECCFGR1.SEC31 is enabled, IM31 can only be accessed with secure access. Non-secure write to this bit is discarded, non-secure read returns 0. When EXTI2_PRIVCFGR1.PRIV31 is disabled, IM31 can be accessed with privilege and unprivileged access. When EXTI2_PRIVCFGR1.PRIV31 is enabled, IM31 can only be accessed with privilege access. Unprivileged write to this bit is discarded and read returns 0. When CID filtering is disabled in EXTI2_E31CIDCFGR this IM31 can be accessed by any processor CID. When CID filtering is enabled in EXTI2_E31CIDCFGR this IM31 can only be accessed by the allowed processor CID. Dis allowed CID write to this IM31 is discarded and read returns 0.
    0=wakeup and interrupt CPU(m) from input event n is masked; 1=wakeup and interrupt CPU(m) from input event n is unmasked. CPU(m) wakeup event and configurable event interrupt generated.
  [30] IM30 — CPUm wakeup with interrupt mask on event input 30.
  [29] IM29 — CPUm wakeup with interrupt mask on event input 29.
  [n] IM{n} (n=0..27) — CPUm wakeup with interrupt mask on event input {n}.
{0x50+0x40*i} EXTI2_C{i}IMR2 (i=1..3) — EXTI2 CPU{i} wakeup with interrupt mask register
  [31] IM63 — CPUm wakeup with interrupt mask on event input 63. When EXTI2_SECCFGR2.SEC63 is disabled, IM63 can be accessed with non-secure and secure access. When EXTI2_SECCFGR2.SEC63 is enabled, IM63 can only be accessed with secure access. Non-secure write to this bit is discarded, non-secure read returns 0. When EXTI2_PRIVCFGR2.PRIV63 is disabled, IM63 can be accessed with privilege and unprivileged access. When EXTI2_PRIVCFGR2.PRIV63 is enabled, IM63 can only be accessed with privilege access. Unprivileged write to this bit is discarded and read returns 0. When CID filtering is disabled in EXTI2_E63CIDCFGR this IM63 can be accessed by any processor CID. When CID filtering is enabled in EXTI2_E63CIDCFGR this IM63 can only be accessed by the allowed processor CID. Dis allowed CID write to this IM63 is discarded and read returns 0.
    0=wakeup and interrupt CPU(m) from input event 63 is masked; 1=wakeup and interrupt CPU(m) from input event 63 is unmasked. CPU(m) wakeup event and configurable event interrupt generated.
  [n-32] IM{n} (n=59..62) — CPUm wakeup with interrupt mask on event input {n}.
  [n-32] IM{n} (n=46..56) — CPUm wakeup with interrupt mask on event input {n}.
  [n-32] IM{n} (n=40..44) — CPUm wakeup with interrupt mask on event input {n}.
  [n-32] IM{n} (n=33..38) — CPUm wakeup with interrupt mask on event input {n}.
{0x60+0x40*i} EXTI2_C{i}IMR3 (i=1..3) — EXTI2 CPU{i} wakeup with interrupt mask register
  [12] IM76 — CPUm wakeup with interrupt mask on event input 76. When EXTI2_SECCFGR3.SEC76 is disabled, IM76 can be accessed with non-secure and secure access. When EXTI2_SECCFGR3.SEC76 is enabled, IM76 can only be accessed with secure access. Non-secure write to this bit is discarded, non-secure read returns 0. When EXTI2_PRIVCFGR3.PRIV76 is disabled, IM76 can be accessed with privilege and unprivileged access. When EXTI2_PRIVCFGR3.PRIV76 is enabled, IM76 can only be accessed with privilege access. Unprivileged write to this bit is discarded and read returns 0. When CID filtering is disabled in EXTI2_E76CIDCFGR this IM76 can be accessed by any processor CID. When CID filtering is enabled in EXTI2_E76CIDCFGR this IM76 can only be accessed by the allowed processor CID. Dis allowed CID write to this IM76 is discarded and read returns 0.
    values as EXTI2_C1IMR1.IM31
  [n-64] IM{n} (n=64..70) — CPUm wakeup with interrupt mask on event input {n}.
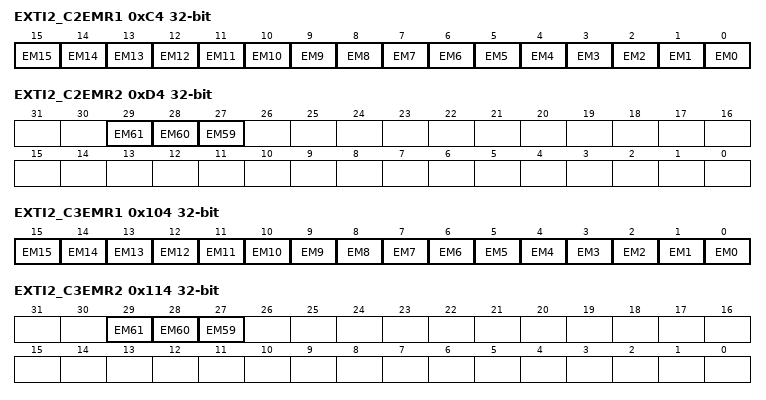
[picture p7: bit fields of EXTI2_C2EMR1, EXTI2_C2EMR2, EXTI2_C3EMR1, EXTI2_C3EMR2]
0xC4 EXTI2_C2EMR1 — EXTI2 CPU2 wakeup with event mask register
  [all] fields
    0=wakeup with event generation from line n is masked; 1=wakeup with event generation from line n is unmasked
  [n] EM{n} (n=0..15) — CPU(m) wakeup with event generation mask on event input n. (where n = 15 to 0) When EXTI2_SECCFGR1.SECENn is disabled, EMn can be accessed with non-secure and secure access. When EXTI2_SECCFGR1.SECENn is enabled, EMn can only be accessed with secure access. Non-secure write to this bit is discarded, non-secure read returns 0. When EXTI2_PRIVCFGR1.PRIVn is disabled, EMn can be accessed with privilege and unprivileged access. When EXTI2_PRIVCFGR1.PRIVn is enabled, EMn can only be accessed with privilege access. Unprivileged write to this bit is discarded and read returns 0. When CID filtering is disabled in EXTI2_EnCIDCFGR this EMn can be accessed by any processor CID. When CID filtering is enabled in EXTI2_EnCIDCFGR this EMn can only be accessed by the allowed processor CID. Dis allowed CID write to this EMn is discarded and read returns 0.
0xD4 EXTI2_C2EMR2 — EXTI2 CPU2 wakeup with event mask register
  [29] EM61 — CPU(m) wakeup with event generation mask on event input 61. When EXTI2_SECCFGR2.SEC61 is disabled, EM61 can be accessed with non-secure and secure access. When EXTI2_SECCFGR2.SEC61 is enabled, EM61 can only be accessed with secure access. Non-secure write to this bit x is discarded, non-secure read returns 0. When EXTI2_PRIVCFGR2.PRIV61 is disabled, EM61 can be accessed with privilege and unprivileged access. When EXTI2_PRIVCFGR2.PRIV61 is enabled, EM61 can only be accessed with privilege access. Unprivileged write to this bit is discarded and read returns 0. When CID filtering is disabled in EXTI2_E61CIDCFGR this EM61 can be accessed by any processor CID. When CID filtering is enabled in EXTI2_E61CIDCFGR this EM61 can only be accessed by the allowed processor CID. Dis allowed CID write to this EM61 is discarded and read returns 0.
    0=wakeup with event generation from line 61 is masked; 1=wakeup with event generation from line 61 is unmasked
  [28] EM60 — CPU(m) wakeup with event generation mask on event input 60.
  [27] EM59 — CPU(m) wakeup with event generation mask on event input 59.
0x104 EXTI2_C3EMR1 — EXTI2 CPU3 wakeup with event mask register
  fields as EXTI2_C2EMR1
0x114 EXTI2_C3EMR2 — EXTI2 CPU3 wakeup with event mask register
  fields as EXTI2_C2EMR2
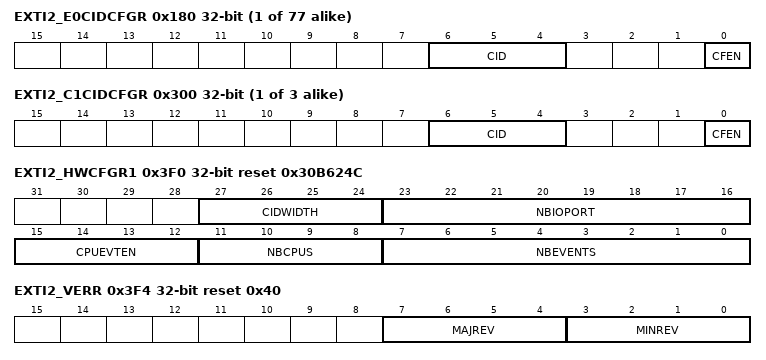
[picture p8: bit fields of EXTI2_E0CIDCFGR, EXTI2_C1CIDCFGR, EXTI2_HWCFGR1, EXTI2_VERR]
{0x180+4i} EXTI2_E{i}CIDCFGR (i=0..76) — EXTI2 event CID Config register
  [6:4] CID — EXTI event n allowed CID value. If CID filtering is disabled in CFEN, these bits are ignored, else: EXITI event n allowed processor CID number.
  [0] CFEN — EXTI event n CID filtering enable
    0=disable EXTI event n filtering. (EXTI event n can be accessed by all CIDs); 1=enable EXTI event n filtering. (EXTI event n can only be accessed by the processor with CID = CPUm CID.)
{0x2FC+4i} EXTI2_C{i}CIDCFGR (i=1..3) — EXTI2 processor {i} CID configuration register
  [6:4] CID — CPUm CID domain identification If CFEN = 0 these bits are ignored and there is no CPUm CID filtering. Else: CPUm CID domain identification number
  [0] CFEN — CID filtering enabled for CPUm EXTI2_CmIMRn and EXTI2_CmEMRn registers
    0=disable the CID filtering for CPUm; 1=enable the CID filtering for CPUm
0x3C0 EXTI2_HWCFGR13 ro reset 0x107F
  [31:0] SEC — HW configuration event security privilege and resource isolation capability.
    0=Non-secure, unprivileged and no resource filtering event; 1=Security, privilege and resource filtering capable event
0x3C4 EXTI2_HWCFGR12 ro reset 0xF9FFDF7E
  fields as EXTI2_HWCFGR13
0x3C8 EXTI2_HWCFGR11 ro reset 0xEFFFFFFF
  fields as EXTI2_HWCFGR13
0x3D8 EXTI2_HWCFGR7 ro
  [31:0] CPUEVENT — HW configuration CPU event generation
    0=No CPU event generated; 1=CPU event generated
0x3DC EXTI2_HWCFGR6 ro reset 0x38000000
  fields as EXTI2_HWCFGR7
0x3E0 EXTI2_HWCFGR5 ro reset 0xFFFF
  fields as EXTI2_HWCFGR7
0x3E4 EXTI2_HWCFGR4 ro reset 0x7
  [31:0] EVENT_TRG — HW configuration event trigger type
    0=Direct event; 1=configurable event
0x3E8 EXTI2_HWCFGR3 ro reset 0x380FC000
  fields as EXTI2_HWCFGR4
0x3EC EXTI2_HWCFGR2 ro reset 0xFFFF
  fields as EXTI2_HWCFGR4
0x3F0 EXTI2_HWCFGR1 ro reset 0x30B624C
  [27:24] CIDWIDTH — CID parameters bit width
  [23:16] NBIOPORT — HW configuration of number of IO ports on EXTI. (n+1)
  [15:12] CPUEVTEN — HW configuration of CPU(m) event output enable.
  [11:8] NBCPUS — HW configuration number of CPUs (n+1)
  [7:0] NBEVENTS — HW configuration number of event (n+1)
0x3F4 EXTI2_VERR ro reset 0x40
  [7:4] MAJREV — Major Revision number
  [3:0] MINREV — Minor Revision number
0x3F8 EXTI2_IPIDR ro reset 0xE0001
  [31:0] IPID — IP Identification
0x3FC EXTI2_SIDR ro reset 0xA3C5DD01
  [31:0] SID — Size Identification
